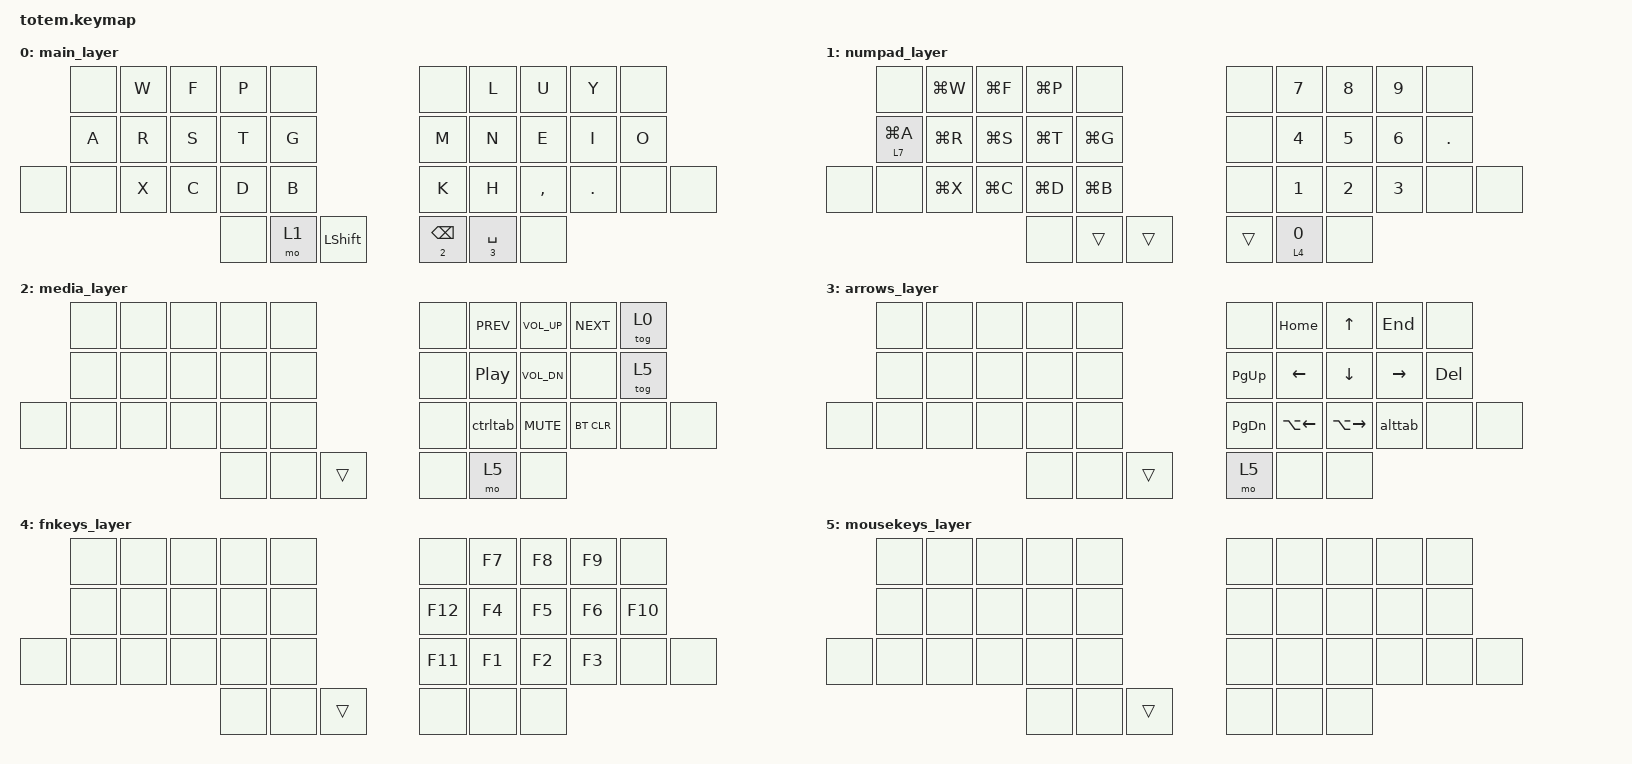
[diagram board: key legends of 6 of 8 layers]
//
//                                                        ▀▀▀▀▀     ▀▀▀▀▀          ▀▀█▀▀
//                                                        ▄▀▀▀▄  ▄  ▄▀▀▀▄  ▄  ▄▀▀▀▄  █  ▄▀▀▀▄
//                                                        █   █  █  █   █  █  █   █  █  █   █
//                                                         ▀▀▀   █   ▀▀▀   █   ▀▀▀   ▀   ▀▀▀
//                                                               █      ▄▄▄█▄▄▄    █   █  
//                                                               ▀      █  █  █     █▄█
//                                                             ▀▀▀▀▀    █  █  █      ▀
//                                                                      ▀  ▀  ▀
//
// ▄▄▄▄▄▄▄▄▄▄▄▄▄▄▄▄▄▄▄▄▄▄▄▄▄▄▄▄▄▄▄▄▄▄▄▄▄▄▄▄▄▄▄▄▄▄▄▄▄▄▄▄▄▄▄▄▄▄▄▄▄▄▄▄▄▄▄▄▄▄▄▄▄▄▄▄▄▄▄▄▄▄▄▄▄▄▄▄▄▄▄▄▄▄▄▄▄▄▄▄▄▄▄▄▄▄▄▄▄▄▄▄▄▄▄▄▄▄▄▄▄▄▄▄▄▄▄▄▄▄▄▄▄▄▄▄▄▄▄▄▄▄▄▄▄▄▄▄▄
       

#include <behaviors.dtsi> 
#include <dt-bindings/zmk/keys.h>
#include <dt-bindings/zmk/bt.h>
#include <dt-bindings/zmk/outputs.h>

#define MAIN 0
#define NUMPAD 1
#define MEDIA 2
#define ARROWS 3
#define FKEYS 4
#define MOUSEKEYS 5
#define ALTTAB 6
#define LEFTARROWS 7

/*
     |  0 |  1 |  2 |  3 |  4 |    |  5 |  6 |  7 |  8 |  9 |
     | 10 | 11 | 12 | 13 | 14 |    | 15 | 16 | 17 | 18 | 19 |
| 20 | 21 | 22 | 23 | 24 | 25 |    | 26 | 27 | 28 | 29 | 30 | 31 | 
     |    |    | 32 | 33 | 34 |    | 35 | 36 | 37 |    |    | 
                                                                  */

/ {
    combos {
        compatible = "zmk,combos";

        //Corner Keys
        combo_topq {
            timeout-ms = <25>;
            key-positions = <1 2>;
            layers = <0>;
            bindings = <&kp Q>;
        };
        combo_q {
            timeout-ms = <25>;
            key-positions = <11 2>;
            layers = <0>;
            bindings = <&kp Q>;
        };
        combo_guiq {
            timeout-ms = <25>;
            key-positions = <1 2>;
            layers = <1>;
            bindings = <&kp LG(Q)>;
        };
        combo_z {
            timeout-ms = <25>;
            key-positions = <22 23>;
            layers = <0>;
            bindings = <&kp Z>;
        };
        combo_z2 {
            timeout-ms = <25>;
            key-positions = <22 12>;
            layers = <0>;
            bindings = <&kp Z>;
        };
        combo_guiz {
            timeout-ms = <25>;
            key-positions = <22 23>;
            layers = <1>;
            bindings = <&kp LG(Z)>;
        };
        combo_j{
            timeout-ms = <25>;
            key-positions = <2 13>;
            layers = <0>;
            bindings = <&kp J>;
        };
        combo_guij{
            timeout-ms = <25>;
            key-positions = <2 3>;
            layers = <1>;
            bindings = <&kp LG(J)>;
        };
        combo_v{
            timeout-ms = <25>;
            key-positions = <23 24>;
            layers = <0>;
            bindings = <&kp V>;
        };
        combo_v2{
            timeout-ms = <25>;
            key-positions = <12 24>;
            layers = <0>;
            bindings = <&kp V>;
        };
        combo_guiv {
            timeout-ms = <25>;
            key-positions = <23 24>;
            layers = <1>;
            bindings = <&kp LG(V)>;
        };


        //Modifiers – Left Hand
        combo_lgui {
            timeout-ms = <25>;
            key-positions = <3 13>;
            layers = <0 1 2 3 4 5>;
            bindings = <&kp LGUI>;
        };
        combo_lalt {
            timeout-ms = <25>;
            key-positions = <2 12>;
            layers = <0 1 2 3 4 5>;
            bindings = <&kp LALT>;
        };
        combo_lctl {
            timeout-ms = <25>;
            key-positions = <1 11>;
            layers = <0 1 2 3 4 5>;
            bindings = <&kp LCTRL>;
        };
        combo_lctlalt {
            timeout-ms = <25>;
            key-positions = <1 11 2 12>;
            layers = <0 1 2 3 4 5>;
            bindings = <&kp LC(LALT)>;
        };
        combo_lctlgui {
            timeout-ms = <25>;
            key-positions = <1 11 3 13>;
            layers = <0 1 2 3 4 5>;
            bindings = <&kp LC(LGUI)>;
        };
        combo_laltgui {
            timeout-ms = <25>;
            key-positions = <2 12 3 13>;
            layers = <0 1 2 3 4 5>;
            bindings = <&kp LA(LGUI)>;
        };


        //Modifiers – Right Hand
        combo_rgui {
            timeout-ms = <25>;
            key-positions = <6 16>;
            layers = <0 1 2 3 4 5>;
            bindings = <&kp LGUI>;
        };
        combo_ralt {
            timeout-ms = <25>;
            key-positions = <7 17>;
            layers = <0 1 2 3 4 5>;
            bindings = <&kp RALT>;
        };
        combo_rctl {
            timeout-ms = <25>;
            key-positions = <8 18>;
            layers = <0 1 2 3 4 5>;
            bindings = <&kp RCTRL>;
        };        


        //Control Keys – Right Hand
        combo_enter_right {
            timeout-ms = <25>;
            key-positions = <17 18>;
	    layers = <0 1 2 4>;
            bindings = <&kp ENTER>;
        };
        combo_tab_right {
            timeout-ms = <25>;
            key-positions = <18 19>;
	    layers = <0 1 2 4>;
            bindings = <&kp TAB>;
        };
        combo_escape_right {
            timeout-ms = <25>;
            key-positions = <7 8>;
	    layers = <0 1 2 4>;
            bindings = <&kp ESC>;
        };
        combo_caps {
            timeout-ms = <25>;
            key-positions = <13 34>;
	    layers = <0 1 2 4>;
            bindings = <&kp CAPS>;
        };
        combo_ins {
            timeout-ms = <25>;
            key-positions = <13 19>;
	    layers = <3>;
            bindings = <&kp INS>;
        };
        combo_numlock {
            timeout-ms = <25>;
            key-positions = <19 29>;
 	    layers = <4>;
            bindings = <&kp KP_NUM>;
        };
        combo_printscreen {
            timeout-ms = <25>;
            key-positions = <19 16>;
 	    layers = <4>;
            bindings = <&kp PSCRN>;
        };
        combo_scrolllock {
            timeout-ms = <25>;
            key-positions = <19 17>;
 	    layers = <4>;
            bindings = <&kp SLCK>;
        };
        combo_pause {
            timeout-ms = <25>;
            key-positions = <19 18>;
 	    layers = <4>;
            bindings = <&kp PAUSE_BREAK>;
        };
     
   
        //Symbols
        combo_quote {
            timeout-ms = <25>;
            key-positions = <7 18>;
	    layers = <0 1 2 4>;
            bindings = <&kp SQT>;
        };
        combo_doublequote {
            timeout-ms = <25>;
            key-positions = <16 7>;
	    layers = <0 1 2 4>;
            bindings = <&kp DQT>;
        };
        combo_semicolon {
            timeout-ms = <25>;
            key-positions = <28 29>;
	    layers = <0 1 2 4>;
            bindings = <&kp SEMI>;
        };
        combo_colon {
            timeout-ms = <25>;
            key-positions = <17 29>;
	    layers = <0 1 2 4>;
            bindings = <&kp COLON>;
        };
        combo_minus {
            timeout-ms = <25>;
            key-positions = <16 17>;
	    layers = <0 1 2 4>;
            bindings = <&kp MINUS>;
        };
        combo_equals {
            timeout-ms = <25>;
            key-positions = <6 7>;
	    layers = <0 1 2 4>;
            bindings = <&kp EQUAL>;
        };
        combo_plus {
            timeout-ms = <25>;
            key-positions = <16 18>;
	    layers = <0 1 2 4>;
            bindings = <&kp PLUS>;
        };
        combo_underscore {
            timeout-ms = <50>;
            key-positions = <27 28>;
	    layers = <0 1 2 4>;
            bindings = <&kp UNDER>;
        };
        combo_hash {
            timeout-ms = <25>;
            key-positions = <6 8>;
	    layers = <0 1 2 4>;
            bindings = <&kp HASH>;
        };
        combo_asterisk {
            timeout-ms = <25>;
            key-positions = <27 29>;
            layers = <0 1 2 4>;
            bindings = <&kp ASTERISK>;
        };
        combo_grave {
            timeout-ms = <25>;
            key-positions = <6 17>;
	    layers = <0 1 2 4>;
            bindings = <&kp GRAVE>;
        };
        combo_tilde {
            timeout-ms = <25>;
            key-positions = <16 17 8>;
            layers = <0 1 2 4>;
            bindings = <&kp TILDE>;
        };
        combo_slash {
            timeout-ms = <25>;
            key-positions = <27 17>;
            layers = <0 1 2 4>;
            bindings = <&kp SLASH>;
        };
        combo_backslash {
            timeout-ms = <25>;
            key-positions = <16 28>;
            layers = <0 1 2 4>;
            bindings = <&kp BACKSLASH>;
        };
        combo_pipe {
            timeout-ms = <25>;
            key-positions = <27 7>;
            layers = <0 1 2 4>;
            bindings = <&kp PIPE>;
        };
        combo_caret {
            timeout-ms = <25>;
            key-positions = <16 7 18>;
            layers = <0 1 2 4>;
            bindings = <&kp CARET>;
        }; 
        combo_percentsign {
            timeout-ms = <25>;
            key-positions = <27 18>;
            layers = <0 1 2 4>;
            bindings = <&kp PERCENT>;
        };
        combo_exclamationmark {
            timeout-ms = <25>;
            key-positions = <6 18>;
            layers = <0 1 2 4>;
            bindings = <&kp EXCLAMATION>;
        };
        combo_questionmark {
            timeout-ms = <25>;
            key-positions = <16 8>;
            layers = <0 1 2 4>;
            bindings = <&kp QUESTION>;
        };
        combo_dollarsign {
            timeout-ms = <25>;
            key-positions = <27 7 18>;
            layers = <0 1 2 4>;
            bindings = <&kp DOLLAR>;
        };
        combo_atsign {
            timeout-ms = <25>;
            key-positions = <6 17 18>;
            layers = <0 1 2 4>;
            bindings = <&kp AT_SIGN>;
        };
        combo_ampersand {
            timeout-ms = <25>;
            key-positions = <16 29>;
            layers = <0 1 2 4>;
            bindings = <&kp AMPERSAND>;
        };
        combo_lpar {
            timeout-ms = <25>;
            key-positions = <19 16>;
            layers = <0 1 2 4>;
            bindings = <&kp LPAR>;
        };
        combo_rpar {
            timeout-ms = <25>;
            key-positions = <19 17>;
            layers = <0 1 2 4>;
            bindings = <&kp RPAR>;
        };
        combo_lbkt {
            timeout-ms = <25>;
            key-positions = <19 6>;
            layers = <0 1 2 4>;
            bindings = <&kp LBKT>;
        };
        combo_rbkt {
            timeout-ms = <25>;
            key-positions = <19 7>;
            layers = <0 1 2 4>;
            bindings = <&kp RBKT>;
        };
        combo_lbrc {
            timeout-ms = <25>;
            key-positions = <19 26>;
            layers = <0 1 2 4>;
            bindings = <&kp LBRC>;
        };
        combo_rbrc {
            timeout-ms = <25>;
            key-positions = <19 27>;
            layers = <0 1 2 4>;
            bindings = <&kp RBRC>;
        };

        
        //Right Hand
        combo_enter_left {
            timeout-ms = <25>;
            key-positions = <11 12>;
            layers = <0 1 2 4>;
            bindings = <&kp ENTER>;
        };
        combo_tab_left {
            timeout-ms = <25>;
            key-positions = <11 12 13>;
            layers = <0 1 2 4>;
            bindings = <&kp LS(TAB)>;
        };
        combo_escape_left {
            timeout-ms = <25>;
            key-positions = <1 2 3>;
            layers = <0 1 2 4>;
            bindings = <&kp ESC>;
        };
        combo_space {
            timeout-ms = <25>;
            key-positions = <22 24>;
            layers = <0 1 2 4>;
            bindings = <&kp SPACE>;
        };
        combo_backspace_left {
            timeout-ms = <25>;
            key-positions = <22 23 24>;
            layers = <0 1 2 4>;
            bindings = <&kp BSPC>;
        };
        combo_equal_left {
            timeout-ms = <25>;
            key-positions = <2 3>;
            layers = <0 1 2 4>;
            bindings = <&kp EQUAL>;
        };
        combo_minus_left {
            timeout-ms = <25>;
            key-positions = <12 13>;
            layers = <0 1 2 4>;
            bindings = <&kp MINUS>;
        };
        combo_arrowup_left {
            timeout-ms = <25>;
            key-positions = <10 2>;
            layers = <0 1 2 4>;
            bindings = <&kp UP>;
        };
        combo_arrowleft_left {
            timeout-ms = <25>;
            key-positions = <10 11>;
            layers = <0 1 2 4>;
            bindings = <&kp LEFT>;
        };
        combo_arrowdown_left {
            timeout-ms = <25>;
            key-positions = <10 12>;
            layers = <0 1 2 4>;
            bindings = <&kp DOWN>;
        };
        combo_arrowright_left {
            timeout-ms = <25>;
            key-positions = <10 13>;
            layers = <0 1 2 4>;
            bindings = <&kp RIGHT>;
        };
        
        

        //Misc
        combo_gfemail {
            timeout-ms = <25>;
            key-positions = <13 6 17 18>;
            layers = <0 1 2 4>;
            bindings = <&gfemail>;
        };
        combo_handle {
            timeout-ms = <25>;
            key-positions = <13 6 17>;
            layers = <0 1 2 4>;
            bindings = <&gfhandle>;
        };
        combo_phonenum {
            timeout-ms = <25>;
            key-positions = <13 6 8>;
            layers = <0 1 2 4>;
            bindings = <&phonenum>;
        };
        combo_name {
            timeout-ms = <25>;
            key-positions = <13 27 17>;
            layers = <0 1 2 4>;
            bindings = <&gfname>;
        };
        combo_screenshot_file {
            timeout-ms = <25>;
            key-positions = <2 24>;
            layers = <0 1 2 3 4>;
            bindings = <&kp LG(LS(N4))>;
        };
        combo_screenshot_clipboard {
            timeout-ms = <25>;
            key-positions = <11 2 24>;
            layers = <0 1 2 3 4>;
            bindings = <&kp LG(LS(LC(N4)))>;
        };
        combo_controlup {
            timeout-ms = <25>;
            key-positions = <11 2 13>;
            layers = <0 1 2 3 4>;
            bindings = <&kp LC(UP)>;
        };
        combo_altbackspace {
            timeout-ms = <25>;
            key-positions = <11 12>;
            layers = <0 1 2 4>;
            bindings = <&kp LA(BSPC)>;
        };
        combo_guik {
            timeout-ms = <25>;
            key-positions = <11 24>;
            layers = <0 1 2 4>;
            bindings = <&kp LG(K)>;
        };
        combo_alt_backspace_left {
            timeout-ms = <25>;
            key-positions = <11 13>;
            layers = <0 1 2 4>;
            bindings = <&kp LA(BSPC)>;
        };
        combo_leftguitab {
            timeout-ms = <25>;
            key-positions = <12 13>;
            layers = <0 1 2 4>;
            bindings = <&kp LG(TAB)>;
        };
        combo_altbackspace2 {
            timeout-ms = <25>;
            key-positions = <27 28>;
	    layers = <3>;
            bindings = <&kp LA(BSPC)>;
        };
        combo_altdel {
            timeout-ms = <25>;
            key-positions = <28 29>;
	    layers = <3>;
            bindings = <&kp LA(DEL)>;
        };
        combo_leftl {
            timeout-ms = <25>;
            key-positions = <13 24>;
            layers = <0 1 2 4>;
            bindings = <&kp L>;
        };

    };
};


/ {
    macros {
    
        gfemail: gfemail {
            label = "gfemail";
            compatible = "zmk,behavior-macro";
            #binding-cells = <0>;
            bindings
                = <&macro_tap_time 1>
                , <&macro_tap &kp G &kp F &kp O &kp L &kp G &kp E &kp R &kp T &kp AT_SIGN &kp G &kp M &kp A &kp I &kp L &kp DOT &kp C &kp O &kp M>
                ;
        };

        gfhandle: gfhandle {
            label = "gfhandle";
            compatible = "zmk,behavior-macro";
            #binding-cells = <0>;
            bindings
                = <&macro_tap_time 1>
                , <&macro_tap &kp G &kp F &kp O &kp L &kp G &kp E &kp R &kp T>
                ;
        };
    
        phonenum: phonenum {
            label = "phonenum";
            compatible = "zmk,behavior-macro";
            #binding-cells = <0>;
            bindings
                = <&macro_tap_time 1>
                , <&macro_tap &kp N6 &kp N0 &kp N8 &kp N3 &kp N0 &kp N1 &kp N5 &kp N4 &kp N2 &kp N8>
                ;
        };

        gfname: gfname {
            label = "gfname";
            compatible = "zmk,behavior-macro";
            #binding-cells = <0>;
            bindings
                = <&macro_tap_time 1>
                , <&macro_tap &kp LS(G) &kp A &kp V &kp I &kp N &kp SPACE &kp LS(F) &kp O &kp L &kp G &kp E &kp R &kp T>
                ;
        };

        alttab: alt_tab_enter {
            label = "alt_tab_enter";
	    compatible = "zmk,behavior-macro";
	    #binding-cells = <0>;
	    wait-ms = <10>;
	    tap-ms = <20>;
	    bindings =
		<&macro_press &kp LGUI>,
		<&macro_tap &kp TAB &to ALTTAB>;
        };

        ctrltab: ctrl_tab_enter {
            label = "ctrl_tab_enter";
	    compatible = "zmk,behavior-macro";
	    #binding-cells = <0>;
	    wait-ms = <10>;
	    tap-ms = <20>;
	    bindings =
		<&macro_press &kp LCTRL>,
		<&macro_tap &kp TAB &to ALTTAB>;
        };

        // macro to activate layer 1, then release alt and move to layer 0 on key release
        mo_at: momentary_release_alt {
	   compatible = "zmk,behavior-macro";
	   label = "momentary_release_alt";
	   #binding-cells = <0>;
	   wait-ms = <0>;
	   tap-ms = <0>;
	   bindings = <&macro_press &mo 3>
		 , <&macro_pause_for_release>
		 , <&macro_release &kp LGUI>
		 , <&macro_tap &to 0>;
       };

        mo_ct: momentary_release_ctrl {
	   compatible = "zmk,behavior-macro";
	   label = "momentary_release_ctrl";
	   #binding-cells = <0>;
	   wait-ms = <0>;
	   tap-ms = <0>;
	   bindings = <&macro_press &mo 2>
		 , <&macro_pause_for_release>
		 , <&macro_release &kp LCTRL>
		 , <&macro_tap &to 0>;
       };
	
    };
};

/ {
    behaviors {
	    lta: layer_tap_release_alttab {
	        compatible = "zmk,behavior-hold-tap";
	        label = "layer_tap_release_alttab";
	        #binding-cells = <2>;
	        flavor = "tap-preferred";
	        tapping-term-ms = <200>;
	        bindings = <&mo_at>, <&kp>;
	    };

	    ltc: layer_tap_release_ctrltab {
	        compatible = "zmk,behavior-hold-tap";
	        label = "layer_tap_release_ctrltab";
	        #binding-cells = <2>;
	        flavor = "tap-preferred";
	        tapping-term-ms = <200>;
	        bindings = <&mo_ct>, <&kp>;
	    };


    };
};


/ {
    keymap {
        compatible = "zmk,keymap";
        label ="Default keymap";

        main_layer {
            bindings = <
                &none  &kp W  &kp F  &kp P  &none                          &none  &kp L  &kp U      &kp Y    &none
                &kp A  &kp R  &kp S  &kp T  &kp G                          &kp M  &kp N  &kp E      &kp I    &kp O
         &none  &none  &kp X  &kp C  &kp D  &kp B                          &kp K  &kp H  &kp COMMA  &kp DOT  &none  &none
                                     &none  &mo 1  &kp LSHFT  &ltc 2 BSPC  &lta 3 SPACE  &none
            >;
        };
        
        numpad_layer {
            bindings = <
                &none        &kp LG(W)  &kp LG(F)  &kp LG(P)  &none                      &none  &kp N7  &kp N8  &kp N9  &none 
                &lt 7 LG(A)  &kp LG(R)  &kp LG(S)  &kp LG(T)  &kp LG(G)                  &none  &kp N4  &kp N5  &kp N6  &kp DOT
         &none  &none        &kp LG(X)  &kp LG(C)  &kp LG(D)  &kp LG(B)                  &none  &kp N1  &kp N2  &kp N3  &none    &none
                                                 &none      &trans     &trans  &trans  &lt 4 N0    &none
            >;
        };
        
        media_layer {
            bindings = <
                &none  &none  &none  &none  &none                 &none  &kp C_PREV  &kp C_VOL_UP  &kp C_NEXT  &tog 0 
                &none  &none  &none  &none  &none                 &none  &kp C_PP    &kp C_VOL_DN  &none       &tog 5
         &none  &none  &none  &none  &none  &none                 &none  &ctrltab    &kp C_MUTE    &bt BT_CLR  &none   &none
                                     &none  &none  &trans  &none  &mo 5       &none
            >;
        };

        arrows_layer {
            bindings = <
                &none  &none  &none  &none  &none                 &none      &kp HOME      &kp UP         &kp END    &none 
                &none  &none  &none  &none  &none                 &kp PG_UP  &kp LEFT      &kp DOWN       &kp RIGHT  &kp DEL
         &none  &none  &none  &none  &none  &none                 &kp PG_DN  &kp LA(LEFT)  &kp LA(RIGHT)  &alttab    &none   &none  
                                     &none  &none  &trans  &mo 5  &none  &none
            >;
        };
        
        fnkeys_layer {
            bindings = <
                &none  &none  &none  &none  &none                 &none    &kp F7  &kp F8  &kp F9  &none
                &none  &none  &none  &none  &none                 &kp F12  &kp F4  &kp F5  &kp F6  &kp F10
         &none  &none  &none  &none  &none  &none                 &kp F11  &kp F1  &kp F2  &kp F3  &none   &none
                                     &none  &none  &trans  &none  &none  &none
            >;
        };
        
        mousekeys_layer {
            bindings = <
                &none  &none  &none  &none  &none                 &none  &none  &none  &none  &none 
                &none  &none  &none  &none  &none                 &none  &none  &none  &none  &none
         &none  &none  &none  &none  &none  &none                 &none  &none  &none  &none  &none  &none
                                     &none  &none  &trans  &none  &none  &none
            >;
        };

	alttab_layer {
            bindings = <
                &none  &none  &none  &none  &none                 &none  &none    &none    &none  &none
                &none  &none  &none  &none  &none                 &none  &none    &none    &none  &none
                &none  &none  &none  &none  &none                 &none  &kp TAB  &kp TAB  &none  &none 
                                     &none  &none  &trans  &none  &none  &none
            >;
        };

	leftarrows_layer {
            bindings = <
                &none  &kp HOME  &kp UP    &kp END    &none                 &none  &none    &none    &none  &none
                &none  &kp LEFT  &kp DOWN  &kp RIGHT  &none                 &none  &none    &none    &none  &none
                &none  &none     &none     &none      &none                 &none  &none    &none    &none  &none
                                           &none      &none  &trans  &none  &none  &none
            >;
        };
               
    };
};
